# STM32H5F5xx register map
File version: 1.0
Registers are 32-bit, read-write, reset 0x0 unless marked. A register's access mark holds for its fields unless they carry their own. Offsets are from the block's base; [hi:lo] are bit positions; {n}, {i} and the like mark numbered series; 'fields as' and 'values as' point back to an identical list.

## GTZC_TZSC1 — Global TrustZone Controller
Base 0x40032400
Same registers: GTZC_TZSC1_S 0x50032400
0x00 CR — TZSC control register
  [0] LCK
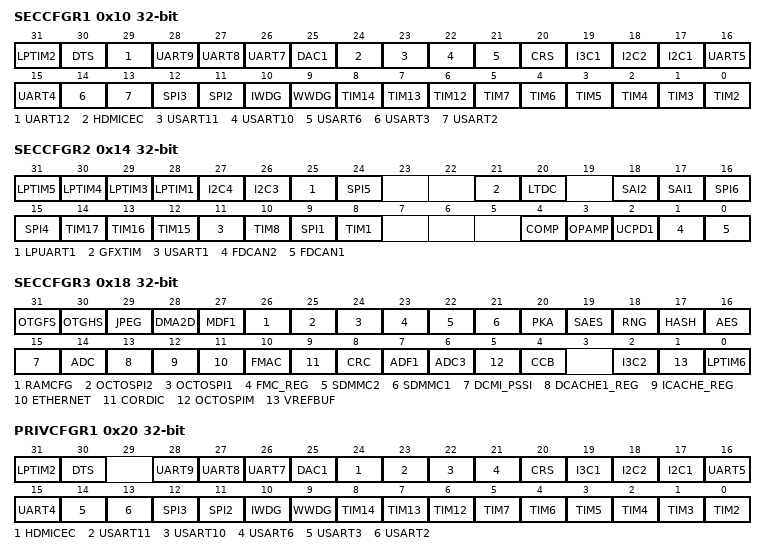
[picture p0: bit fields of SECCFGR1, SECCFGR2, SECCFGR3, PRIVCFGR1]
0x10 SECCFGR1 — TZSC secure configuration register 1
  [31] LPTIM2, [30] DTS, [29] UART12, [28] UART9, [27] UART8, [26] UART7, [25] DAC1, [24] HDMICEC, [23] USART11, [22] USART10, [21] USART6, [20] CRS, [19] I3C1, [18] I2C2, [17] I2C1, [16] UART5, [15] UART4, [14] USART3, [13] USART2, [12] SPI3, [11] SPI2, [10] IWDG, [9] WWDG, [8] TIM14, [7] TIM13, [6] TIM12, [n-2] TIM{n} (n=2..7)
0x14 SECCFGR2 — TZSC secure configuration register 2
  [31] LPTIM5, [30] LPTIM4, [29] LPTIM3, [28] LPTIM1, [27] I2C4, [26] I2C3, [25] LPUART1, [24] SPI5, [21] GFXTIM, [20] LTDC, [18] SAI2, [17] SAI1, [16] SPI6, [15] SPI4, [14] TIM17, [13] TIM16, [12] TIM15, [11] USART1, [10] TIM8, [9] SPI1, [8] TIM1, [4] COMP, [3] OPAMP, [2] UCPD1, [1] FDCAN2, [0] FDCAN1
0x18 SECCFGR3 — TZSC secure configuration register 3
  [31] OTGFS, [30] OTGHS, [29] JPEG, [28] DMA2D, [27] MDF1, [26] RAMCFG, [25] OCTOSPI2, [24] OCTOSPI1, [23] FMC_REG, [22] SDMMC2, [21] SDMMC1, [20] PKA, [19] SAES, [18] RNG, [17] HASH, [16] AES, [15] DCMI_PSSI, [14] ADC, [13] DCACHE1_REG, [12] ICACHE_REG, [11] ETHERNET, [10] FMAC, [9] CORDIC, [8] CRC, [7] ADF1, [6] ADC3, [5] OCTOSPIM, [4] CCB, [2] I3C2, [1] VREFBUF, [0] LPTIM6
0x20 PRIVCFGR1 — TZSC privilege configuration register 1
  [31] LPTIM2, [30] DTS, [28] UART9, [27] UART8, [26] UART7, [25] DAC1, [24] HDMICEC, [23] USART11, [22] USART10, [21] USART6, [20] CRS, [19] I3C1, [18] I2C2, [17] I2C1, [16] UART5, [15] UART4, [14] USART3, [13] USART2, [12] SPI3, [11] SPI2, [10] IWDG, [9] WWDG, [8] TIM14, [7] TIM13, [6] TIM12, [n-2] TIM{n} (n=2..7)
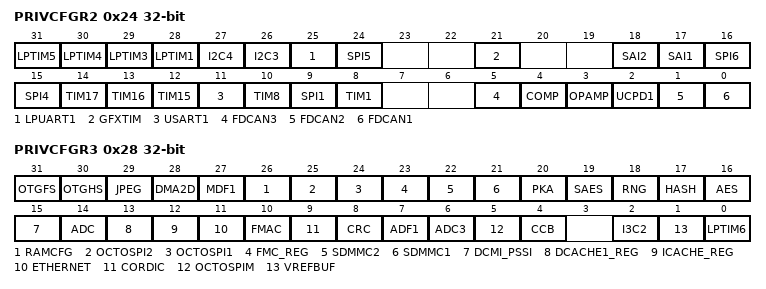
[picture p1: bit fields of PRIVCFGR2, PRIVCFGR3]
0x24 PRIVCFGR2 — TZSC privilege configuration register 2
  [31] LPTIM5, [30] LPTIM4, [29] LPTIM3, [28] LPTIM1, [27] I2C4, [26] I2C3, [25] LPUART1, [24] SPI5, [21] GFXTIM, [18] SAI2, [17] SAI1, [16] SPI6, [15] SPI4, [14] TIM17, [13] TIM16, [12] TIM15, [11] USART1, [10] TIM8, [9] SPI1, [8] TIM1, [5] FDCAN3, [4] COMP, [3] OPAMP, [2] UCPD1, [1] FDCAN2, [0] FDCAN1
0x28 PRIVCFGR3 — TZSC privilege configuration register 3
  fields as SECCFGR3
{0x30+0x10*i} MPCWM{i}ACFGR (i=1..5) — TZSC memory {i} sub-region A watermark configuration register
{0x34+0x10*i} MPCWM{i}AR (i=1..5) — TZSC memory {i} sub-region A watermark register
{0x38+0x10*i} MPCWM{i}BCFGR (i=1..5) — TZSC memory {i} sub-region B watermark configuration register
{0x3C+0x10*i} MPCWM{i}BR (i=1..5) — TZSC memory {i} sub-region B watermark register

## GTZC_TZIC1
Base 0x40032800
Same registers: GTZC_TZIC1_S 0x50032800
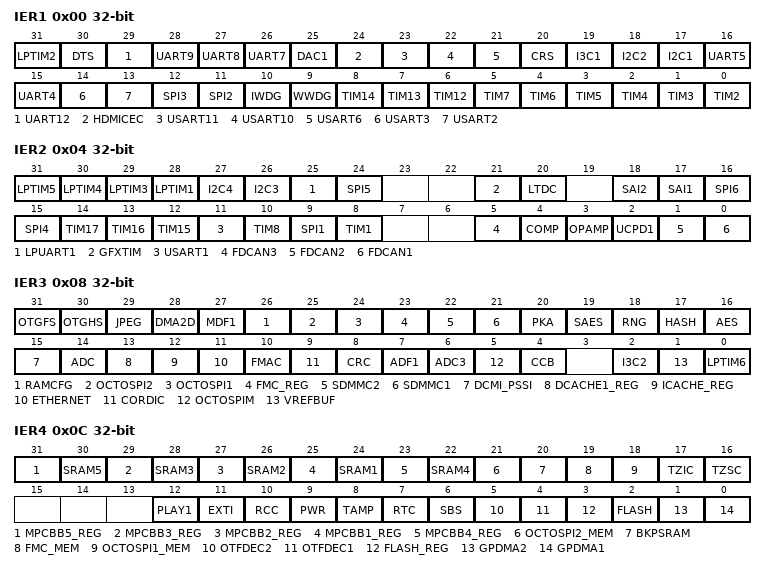
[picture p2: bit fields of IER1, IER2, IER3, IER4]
0x00 IER1 — TZIC interrupt enable register 1
  [31] LPTIM2, [30] DTS, [29] UART12, [28] UART9, [27] UART8, [26] UART7, [25] DAC1, [24] HDMICEC, [23] USART11, [22] USART10, [21] USART6, [20] CRS, [19] I3C1, [18] I2C2, [17] I2C1, [16] UART5, [15] UART4, [14] USART3, [13] USART2, [12] SPI3, [11] SPI2, [10] IWDG, [9] WWDG, [8] TIM14, [7] TIM13, [6] TIM12, [n-2] TIM{n} (n=2..7)
0x04 IER2 — TZIC interrupt enable register 2
  [31] LPTIM5, [30] LPTIM4, [29] LPTIM3, [28] LPTIM1, [27] I2C4, [26] I2C3, [25] LPUART1, [24] SPI5, [21] GFXTIM, [20] LTDC, [18] SAI2, [17] SAI1, [16] SPI6, [15] SPI4, [14] TIM17, [13] TIM16, [12] TIM15, [11] USART1, [10] TIM8, [9] SPI1, [8] TIM1, [5] FDCAN3, [4] COMP, [3] OPAMP, [2] UCPD1, [1] FDCAN2, [0] FDCAN1
0x08 IER3 — TZIC interrupt enable register 3
  [31] OTGFS, [30] OTGHS, [29] JPEG, [28] DMA2D, [27] MDF1, [26] RAMCFG, [25] OCTOSPI2, [24] OCTOSPI1, [23] FMC_REG, [22] SDMMC2, [21] SDMMC1, [20] PKA, [19] SAES, [18] RNG, [17] HASH, [16] AES, [15] DCMI_PSSI, [14] ADC, [13] DCACHE1_REG, [12] ICACHE_REG, [11] ETHERNET, [10] FMAC, [9] CORDIC, [8] CRC, [7] ADF1, [6] ADC3, [5] OCTOSPIM, [4] CCB, [2] I3C2, [1] VREFBUF, [0] LPTIM6
0x0C IER4 — TZIC interrupt enable register 4
  [31] MPCBB5_REG, [30] SRAM5, [29] MPCBB3_REG, [28] SRAM3, [27] MPCBB2_REG, [26] SRAM2, [25] MPCBB1_REG, [24] SRAM1, [23] MPCBB4_REG, [22] SRAM4, [21] OCTOSPI2_MEM, [20] BKPSRAM, [19] FMC_MEM, [18] OCTOSPI1_MEM, [17] TZIC, [16] TZSC, [12] PLAY1, [11] EXTI, [10] RCC, [9] PWR, [8] TAMP, [7] RTC, [6] SBS, [5] OTFDEC2, [4] OTFDEC1, [3] FLASH_REG, [2] FLASH, [1] GPDMA2, [0] GPDMA1
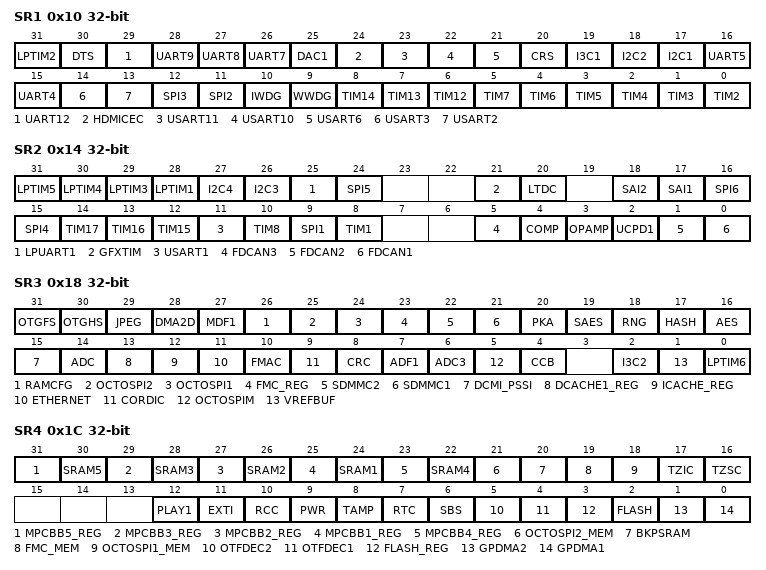
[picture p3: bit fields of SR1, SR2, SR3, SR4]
0x10 SR1 — TZIC status register 1
  fields as IER1
0x14 SR2 — TZIC status register 2
  fields as IER2
0x18 SR3 — TZIC status register 3
  fields as IER3
0x1C SR4 — TZIC status register 4
  fields as IER4
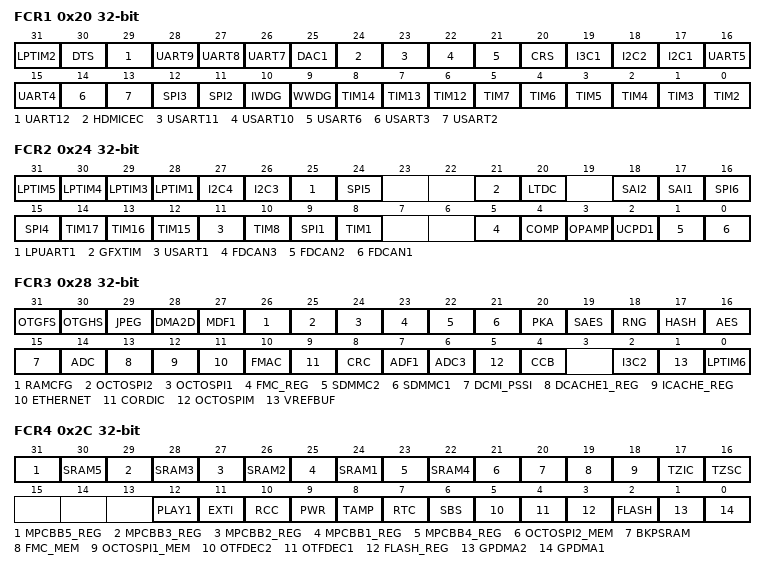
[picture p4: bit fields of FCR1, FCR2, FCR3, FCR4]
0x20 FCR1 — TZIC flag clear register 1
  fields as IER1
0x24 FCR2 — TZIC flag clear register 2
  fields as IER2
0x28 FCR3 — TZIC flag clear register 3
  fields as IER3
0x2C FCR4 — TZIC flag clear register 3
  fields as IER4
